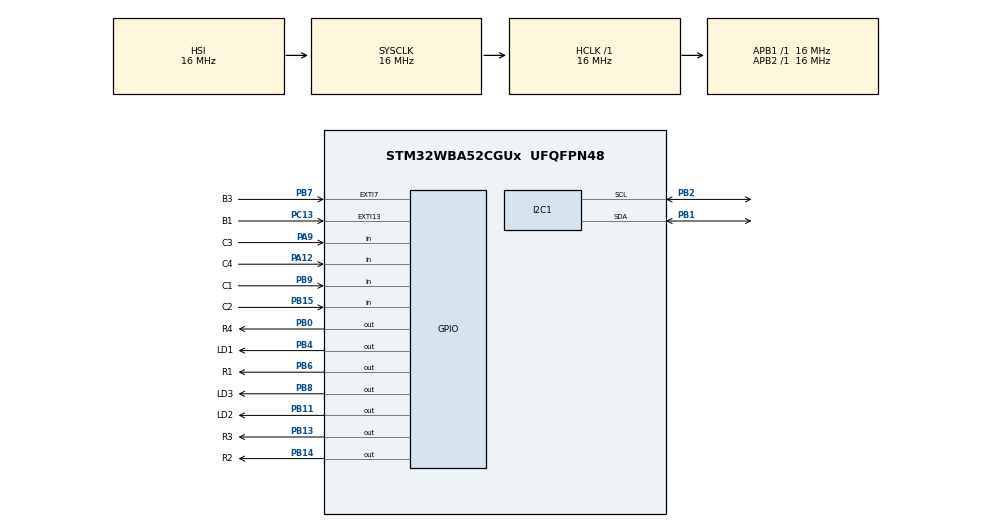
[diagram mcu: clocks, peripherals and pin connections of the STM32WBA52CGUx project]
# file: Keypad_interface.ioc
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CORTEX_M33_NS.userName=CORTEX_M33
I2C1.Timing=0x00303D5B
Mcu.Family=STM32WBA
Mcu.Name=STM32WBA52CGUx
Mcu.Package=UFQFPN48
NVIC.EXTI13_IRQn=true\:0\:0\:false\:false\:true\:true\:true\:true
NVIC.EXTI7_IRQn=true\:0\:0\:false\:false\:true\:true\:true\:true
NVIC.PriorityGroup=NVIC_PRIORITYGROUP_4
OSC_IN.GPIO_Label=RCC_OSC_IN
OSC_IN.Mode=HSE-External-Oscillator
OSC_IN.Signal=RCC_OSC_IN
OSC_OUT.GPIO_Label=RCC_OSC_OUT
OSC_OUT.Mode=HSE-External-Oscillator
OSC_OUT.Signal=RCC_OSC_OUT
PA12.GPIO_Label=C4
PA12.Signal=GPIO_Input
PA13\ (JTMS/SWDIO).GPIO_Label=DEBUG_JTMS-SWDIO
PA13\ (JTMS/SWDIO).Signal=DEBUG_JTMS-SWDIO
PA14\ (JTCK/SWCLK).GPIO_Label=DEBUG_JTCK-SWCLK
PA14\ (JTCK/SWCLK).Signal=DEBUG_JTCK-SWCLK
PA8.GPIO_Label=USART1_RX
PA8.Signal=USART1_RX
PA9.GPIO_Label=C3
PA9.Signal=GPIO_Input
PB0.GPIO_Label=R4
PB0.Signal=GPIO_Output
PB1.Mode=I2C
PB1.Signal=I2C1_SDA
PB11.GPIO_Label=LD2
PB11.GPIO_Speed=GPIO_SPEED_FREQ_HIGH
PB11.Signal=GPIO_Output
PB12.GPIO_Label=USART1_TX
PB12.Signal=USART1_TX
PB13.GPIO_Label=R3
PB13.Signal=GPIO_Output
PB14.GPIO_Label=R2
PB14.Signal=GPIO_Output
PB15.GPIO_Label=C2
PB15.Signal=GPIO_Input
PB2.Mode=I2C
PB2.Signal=I2C1_SCL
PB4\ (NJTRST).GPIO_Label=LD1
PB4\ (NJTRST).GPIO_Speed=GPIO_SPEED_FREQ_HIGH
PB4\ (NJTRST).Signal=GPIO_Output
PB6.GPIO_Label=R1
PB6.Signal=GPIO_Output
PB7.GPIO_Label=B3
PB7.GPIO_PuPd=GPIO_PULLUP
PB7.Signal=GPXTI7
PB8.GPIO_Label=LD3
PB8.GPIO_Speed=GPIO_SPEED_FREQ_HIGH
PB8.Signal=GPIO_Output
PB9.GPIO_Label=C1
PB9.Signal=GPIO_Input
PC13.GPIO_Label=B1
PC13.GPIO_PuPd=GPIO_PULLUP
PC13.Signal=GPXTI13
PC14-OSC32_IN.GPIO_Label=RCC_OSC32_IN
PC14-OSC32_IN.Signal=RCC_OSC32_IN
PC15-OSC32_OUT.GPIO_Label=RCC_OSC32_OUT
PC15-OSC32_OUT.Signal=RCC_OSC32_OUT
ProjectManager.HeapSize=0x200
ProjectManager.StackSize=0x400
ProjectManager.TargetToolchain=STM32CubeIDE
RCC.ADCFreq_Value=16000000
RCC.AHBFreq_Value=16000000
RCC.APB1Freq_Value=16000000
RCC.APB1TimFreq_Value=16000000
RCC.APB2Freq_Value=16000000
RCC.APB2TimFreq_Value=16000000
RCC.CortexFreq_Value=2000000
RCC.HCLKFreq_Value=16000000
RCC.HSE_VALUE=32000000
RCC.HSI_VALUE=16000000
RCC.LSE_VALUE=32768
RCC.PWR_Regulator_Voltage_Scale=PWR_REGULATOR_VOLTAGE_SCALE1
RCC.SYSCLKFreq_VALUE=16000000
RCC.VCOOutputFreq_Value=2064000000
VP_CORTEX_M33_NS_VS_Hclk.Mode=Hclk_Mode
VP_ICACHE_VS_ICACHE.Mode=DirectMappedCache
VP_MEMORYMAP_VS_MEMORYMAP.Mode=CurAppReg
VP_PWR_VS_SECSignals.Mode=Security/Privilege
board=NUCLEO-WBA52CG

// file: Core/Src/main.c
/* USER CODE BEGIN Header */
/**
  ******************************************************************************
  * @file           : main.c
  * @brief          : Main program body
  ******************************************************************************
  * @attention
  *
  * Copyright (c) 2024 STMicroelectronics.
  * All rights reserved.
  *
  * This software is licensed under terms that can be found in the LICENSE file
  * in the root directory of this software component.
  * If no LICENSE file comes with this software, it is provided AS-IS.
  *
  ******************************************************************************
  */
/* USER CODE END Header */
#include "main.h"
#include"i2c-lcd.h"
#include <string.h> // For strcmp
#include <stdio.h>  // For memset/* Private includes ----------------------------------------------------------*/

I2C_HandleTypeDef hi2c1;

void SystemClock_Config(void);
static void MX_GPIO_Init(void);
static void MX_ICACHE_Init(void);
static void MX_I2C1_Init(void);

/*
char keypad_scan[4][4]={{'D','0','#','*'},
			            {'C','8','9','7'},
					    {'B','5','6','4'},
	                    {'A','2','3','1'}};
*/

#define INPUT_SIZE 5 // Define size to include null terminator
#define MUSK_SIZE 5  // Size for the masked input
char input[INPUT_SIZE];
char MUSK[MUSK_SIZE]; // Array to store masked input
int i = 0;
int j = 0; // Index for masked input
int last_key = 0;

// Presumably defined elsewhere
const char* pass = "1234"; // Example password

unsigned char num;

char keypad_press()
{

	HAL_GPIO_WritePin(GPIOB,R1_Pin|R4_Pin|R2_Pin|R3_Pin, GPIO_PIN_SET);
	HAL_GPIO_WritePin(GPIOB,R1_Pin, GPIO_PIN_RESET);
	if((HAL_GPIO_ReadPin(GPIOB, C1_Pin)== 0)){HAL_Delay(250); num = 'D';}
	if((HAL_GPIO_ReadPin(GPIOB, C2_Pin)== 0)){HAL_Delay(250); num = 'c';}
	if((HAL_GPIO_ReadPin(GPIOA, C3_Pin)== 0)){HAL_Delay(250); num = 'B';}
	if((HAL_GPIO_ReadPin(GPIOA, C4_Pin)== 0)){HAL_Delay(250); num = 'A';}
	HAL_GPIO_WritePin(GPIOB,R1_Pin, GPIO_PIN_SET);
	HAL_GPIO_WritePin(GPIOB,R2_Pin, GPIO_PIN_RESET);
	if((HAL_GPIO_ReadPin(GPIOB, C1_Pin)== 0)){HAL_Delay(250);  num = '0';}
	if((HAL_GPIO_ReadPin(GPIOB, C2_Pin)== 0)){HAL_Delay(250);  num = '8';}
	if((HAL_GPIO_ReadPin(GPIOA, C3_Pin)== 0)){HAL_Delay(250);  num = '5';}
	if((HAL_GPIO_ReadPin(GPIOA, C4_Pin)== 0)){HAL_Delay(250);  num = '2';}
	HAL_GPIO_WritePin(GPIOB,R2_Pin, GPIO_PIN_SET);
	HAL_GPIO_WritePin(GPIOB,R3_Pin, GPIO_PIN_RESET);
	if((HAL_GPIO_ReadPin(GPIOB, C1_Pin)== 0)){HAL_Delay(250);  num = '#';}
	if((HAL_GPIO_ReadPin(GPIOB, C2_Pin)== 0)){HAL_Delay(250);  num = '9';}
	if((HAL_GPIO_ReadPin(GPIOA, C3_Pin)== 0)){HAL_Delay(250);  num = '6';}
	if((HAL_GPIO_ReadPin(GPIOA, C4_Pin)== 0)){HAL_Delay(250);  num = '3';}
	HAL_GPIO_WritePin(GPIOB,R3_Pin, GPIO_PIN_SET);
	HAL_GPIO_WritePin(GPIOB,R4_Pin, GPIO_PIN_RESET);
	if((HAL_GPIO_ReadPin(GPIOB, C1_Pin)== 0)){HAL_Delay(250);  num = '*';}
	if((HAL_GPIO_ReadPin(GPIOB, C2_Pin)== 0)){HAL_Delay(250);  num = '7';}
	if((HAL_GPIO_ReadPin(GPIOA, C3_Pin)== 0)){HAL_Delay(250);  num = '4';}
	if((HAL_GPIO_ReadPin(GPIOA, C4_Pin)== 0)){HAL_Delay(250);  num = '1';}
	HAL_GPIO_WritePin(GPIOB,R4_Pin, GPIO_PIN_SET);

    if(num != '\0')
    {
    	return num;
    }
    else
    {
    	return 0;
    }
}

unsigned char Enter_Password() {
    char key = keypad_press(); // Read the key from the keypad
    int result = 0; // Initialize result for comparison

    if (key != 0 && key != last_key) {
        if (i < INPUT_SIZE - 1) { // Ensure there's space for the null terminator
            input[i++] = key; // Store the actual key
            input[i] = '\0'; // Null-terminate the string

            if (j < MUSK_SIZE - 1) { // Ensure space for the masked input
                MUSK[j++] = '*'; // Store a mask character
                MUSK[j] = '\0'; // Null-terminate the masked string
            }

            lcd_put_cur(1, 0);
            lcd_send_string(MUSK); // Display the masked input
        }

        last_key = key; // Update last_key to the currently pressed key
    } else if (key == 0) {
        last_key = 0; // Reset last_key when no key is pressed
    }

    if (i == 4) { // Check if the password is of expected length
        result = strcmp(pass, input);

        lcd_put_cur(1, 0);
        if (result == 0) {
            lcd_send_string("match  "); // Display "match"
        } else {
            lcd_send_string("not match");
            HAL_Delay(1000);
            lcd_clear();
        }

        // Reset input for the next attempt
        memset(input, 0, INPUT_SIZE); // Clear the input buffer
        memset(MUSK, 0, MUSK_SIZE); // Clear the masked input
        i = 0; // Reset index for next input
        j = 0; // Reset masked input index
    }

    return (i == 4 && result == 0) ? 1 : 0; // Return 1 if password matches, else return 0
}

int main(void)
{

  /* MCU Configuration--------------------------------------------------------*/

  /* Reset of all peripherals, Initializes the Flash interface and the Systick. */
  HAL_Init();

  /* Configure the system clock */
  SystemClock_Config();

  /* Initialize all configured peripherals */
  MX_GPIO_Init();
  MX_ICACHE_Init();
  MX_I2C1_Init();
  /* USER CODE BEGIN 2 */
  lcd_init();
  lcd_put_cur(0,0);
  lcd_send_string("lcd start");
  HAL_Delay(1000);
  lcd_clear();

  /* USER CODE END 2 */

while (1) {

	Enter_Password();

}
  /* Infinite loop */
  /* USER CODE BEGIN WHILE */

	}
    /* USER CODE BEGIN 3 */
  /* USER CODE END 3 *

/*
  * @brief System Clock Configuration
  * @retval None
  */

void SystemClock_Config(void)
{
  RCC_OscInitTypeDef RCC_OscInitStruct = {0};
  RCC_ClkInitTypeDef RCC_ClkInitStruct = {0};

  /** Configure the main internal regulator output voltage
  */
  if (HAL_PWREx_ControlVoltageScaling(PWR_REGULATOR_VOLTAGE_SCALE1) != HAL_OK)
  {
    Error_Handler();
  }

  /** Initializes the CPU, AHB and APB busses clocks
  */
  RCC_OscInitStruct.OscillatorType = RCC_OSCILLATORTYPE_HSI;
  RCC_OscInitStruct.HSIState = RCC_HSI_ON;
  RCC_OscInitStruct.HSICalibrationValue = RCC_HSICALIBRATION_DEFAULT;
  RCC_OscInitStruct.PLL1.PLLState = RCC_PLL_NONE;
  if (HAL_RCC_OscConfig(&RCC_OscInitStruct) != HAL_OK)
  {
    Error_Handler();
  }

  /** Initializes the CPU, AHB and APB busses clocks
  */
  RCC_ClkInitStruct.ClockType = RCC_CLOCKTYPE_HCLK|RCC_CLOCKTYPE_SYSCLK
                              |RCC_CLOCKTYPE_PCLK1|RCC_CLOCKTYPE_PCLK2
                              |RCC_CLOCKTYPE_PCLK7|RCC_CLOCKTYPE_HCLK5;
  RCC_ClkInitStruct.SYSCLKSource = RCC_SYSCLKSOURCE_HSI;
  RCC_ClkInitStruct.AHBCLKDivider = RCC_SYSCLK_DIV1;
  RCC_ClkInitStruct.APB1CLKDivider = RCC_HCLK_DIV1;
  RCC_ClkInitStruct.APB2CLKDivider = RCC_HCLK_DIV1;
  RCC_ClkInitStruct.APB7CLKDivider = RCC_HCLK_DIV1;
  RCC_ClkInitStruct.AHB5_PLL1_CLKDivider = RCC_SYSCLK_PLL1_DIV1;
  RCC_ClkInitStruct.AHB5_HSEHSI_CLKDivider = RCC_SYSCLK_HSEHSI_DIV1;

  if (HAL_RCC_ClockConfig(&RCC_ClkInitStruct, FLASH_LATENCY_0) != HAL_OK)
  {
    Error_Handler();
  }
}

static void MX_I2C1_Init(void)
{

  hi2c1.Instance = I2C1;
  hi2c1.Init.Timing = 0x00303D5B;
  hi2c1.Init.OwnAddress1 = 0;
  hi2c1.Init.AddressingMode = I2C_ADDRESSINGMODE_7BIT;
  hi2c1.Init.DualAddressMode = I2C_DUALADDRESS_DISABLE;
  hi2c1.Init.OwnAddress2 = 0;
  hi2c1.Init.OwnAddress2Masks = I2C_OA2_NOMASK;
  hi2c1.Init.GeneralCallMode = I2C_GENERALCALL_DISABLE;
  hi2c1.Init.NoStretchMode = I2C_NOSTRETCH_DISABLE;
  if (HAL_I2C_Init(&hi2c1) != HAL_OK)
  {
    Error_Handler();
  }

  /** Configure Analogue filter
  */
  if (HAL_I2CEx_ConfigAnalogFilter(&hi2c1, I2C_ANALOGFILTER_ENABLE) != HAL_OK)
  {
    Error_Handler();
  }

  /** Configure Digital filter
  */
  if (HAL_I2CEx_ConfigDigitalFilter(&hi2c1, 0) != HAL_OK)
  {
    Error_Handler();
  }

}

static void MX_ICACHE_Init(void)
{

  /** Enable instruction cache in 1-way (direct mapped cache)
  */
  if (HAL_ICACHE_ConfigAssociativityMode(ICACHE_1WAY) != HAL_OK)
  {
    Error_Handler();
  }
  if (HAL_ICACHE_Enable() != HAL_OK)
  {
    Error_Handler();
  }

}

static void MX_GPIO_Init(void)
{
  GPIO_InitTypeDef GPIO_InitStruct = {0};

  /* GPIO Ports Clock Enable */
  __HAL_RCC_GPIOB_CLK_ENABLE();
  __HAL_RCC_GPIOA_CLK_ENABLE();
  __HAL_RCC_GPIOC_CLK_ENABLE();

  /*Configure GPIO pin Output Level */
  HAL_GPIO_WritePin(GPIOB,R1_Pin|LD1_Pin
                          |R4_Pin|R2_Pin|R3_Pin, GPIO_PIN_RESET);

  /*Configure GPIO pin : USART1_TX_Pin */
  GPIO_InitStruct.Pin = USART1_TX_Pin;
  GPIO_InitStruct.Mode = GPIO_MODE_AF_PP;
  GPIO_InitStruct.Pull = GPIO_NOPULL;
  GPIO_InitStruct.Speed = GPIO_SPEED_FREQ_LOW;
  GPIO_InitStruct.Alternate = GPIO_AF7_USART1;
  HAL_GPIO_Init(USART1_TX_GPIO_Port, &GPIO_InitStruct);

  /*Configure GPIO pin : USART1_RX_Pin */
  GPIO_InitStruct.Pin = USART1_RX_Pin;
  GPIO_InitStruct.Mode = GPIO_MODE_AF_PP;
  GPIO_InitStruct.Pull = GPIO_NOPULL;
  GPIO_InitStruct.Speed = GPIO_SPEED_FREQ_LOW;
  GPIO_InitStruct.Alternate = GPIO_AF7_USART1;
  HAL_GPIO_Init(USART1_RX_GPIO_Port, &GPIO_InitStruct);

  /*Configure GPIO pins : C1_Pin C2_Pin */
  GPIO_InitStruct.Pin = C1_Pin|C2_Pin;
  GPIO_InitStruct.Mode = GPIO_MODE_INPUT;
  GPIO_InitStruct.Pull = GPIO_PULLUP;
  HAL_GPIO_Init(GPIOB, &GPIO_InitStruct);

  /*Configure GPIO pins : R1_Pin R4_Pin R2_Pin R3_Pin */
  GPIO_InitStruct.Pin = R1_Pin|R4_Pin|R2_Pin|R3_Pin;
  GPIO_InitStruct.Mode = GPIO_MODE_OUTPUT_PP;
  GPIO_InitStruct.Pull = GPIO_PULLUP;
  GPIO_InitStruct.Speed = GPIO_SPEED_FREQ_LOW;
  HAL_GPIO_Init(GPIOB, &GPIO_InitStruct);

  /*Configure GPIO pins : C4_Pin C3_Pin */
  GPIO_InitStruct.Pin = C4_Pin|C3_Pin;
  GPIO_InitStruct.Mode = GPIO_MODE_INPUT;
  GPIO_InitStruct.Pull = GPIO_PULLUP;
  HAL_GPIO_Init(GPIOA, &GPIO_InitStruct);

  /* EXTI interrupt init*/
  HAL_NVIC_SetPriority(EXTI7_IRQn, 0, 0);
  HAL_NVIC_EnableIRQ(EXTI7_IRQn);

  HAL_NVIC_SetPriority(EXTI13_IRQn, 0, 0);
  HAL_NVIC_EnableIRQ(EXTI13_IRQn);

}

void Error_Handler(void)
{
  __disable_irq();
  while (1)
  {
  }
}
